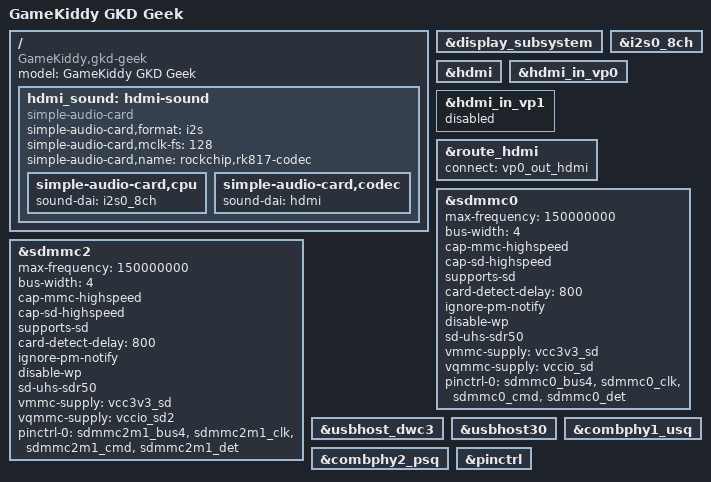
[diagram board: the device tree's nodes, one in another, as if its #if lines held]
// SPDX-License-Identifier: (GPL-2.0+ OR MIT)
/*
 * Copyright (c) 2020 Rockchip Electronics Co., Ltd. *
 */

/dts-v1/;

//#define avrmanhdmi


#include "rk3566-gkd-geek-compute-module.dtsi"

#ifndef avrmanhdmi

#include "rk3566-gkd-geek-lcd.dtsi"
#endif


/ {
	model = "GameKiddy GKD Geek";
	compatible = "GameKiddy,gkd-geek", "rockchip,rk3566";

#ifdef avrmanhdmi
	hdmi_sound: hdmi-sound {
		compatible = "simple-audio-card";
		simple-audio-card,format = "i2s";
		simple-audio-card,mclk-fs = <128>;
		simple-audio-card,name = "rockchip,rk817-codec";

		simple-audio-card,cpu {
				sound-dai = <&i2s0_8ch>;
		};
		simple-audio-card,codec {
				sound-dai = <&hdmi>;
		};
	};
#endif

};

&display_subsystem {
    status = "okay";
};


#ifdef avrmanhdmi

&i2s0_8ch {
	status = "okay";
};

&hdmi {
	status = "okay";
};

&hdmi_in_vp0 {
	status = "okay";
};

&hdmi_in_vp1 {
	status = "disabled";
};

&hdmi_sound {
	status = "okay";
};

&route_hdmi {
	status = "okay";
	connect = <&vp0_out_hdmi>;
};

#endif


&sdmmc0 {
	max-frequency = <150000000>;
	bus-width = <4>;
	cap-mmc-highspeed;
	cap-sd-highspeed;
	supports-sd;
	card-detect-delay = <800>;
	ignore-pm-notify;
	disable-wp;
	sd-uhs-sdr50;
	vmmc-supply = <&vcc3v3_sd>;
	vqmmc-supply = <&vccio_sd>;
	pinctrl-names = "default";
	pinctrl-0 = <&sdmmc0_bus4 &sdmmc0_clk &sdmmc0_cmd &sdmmc0_det>;
	status = "okay";
};

&sdmmc2 {
	max-frequency = <150000000>;
	bus-width = <4>;
	cap-mmc-highspeed;
	cap-sd-highspeed;
	supports-sd;
	card-detect-delay = <800>;
	ignore-pm-notify;
	disable-wp;
	sd-uhs-sdr50;
	vmmc-supply = <&vcc3v3_sd>;
	vqmmc-supply = <&vccio_sd2>;
	pinctrl-names = "default";
	pinctrl-0 = <&sdmmc2m1_bus4 &sdmmc2m1_clk &sdmmc2m1_cmd &sdmmc2m1_det>;
	status = "okay";
};

&usbhost_dwc3 {
	status = "okay";
};

&usbhost30 {
	status = "okay";
};

&combphy1_usq {
	status = "okay";
};

&combphy2_psq {
	status = "okay";
};


&pinctrl {

};
